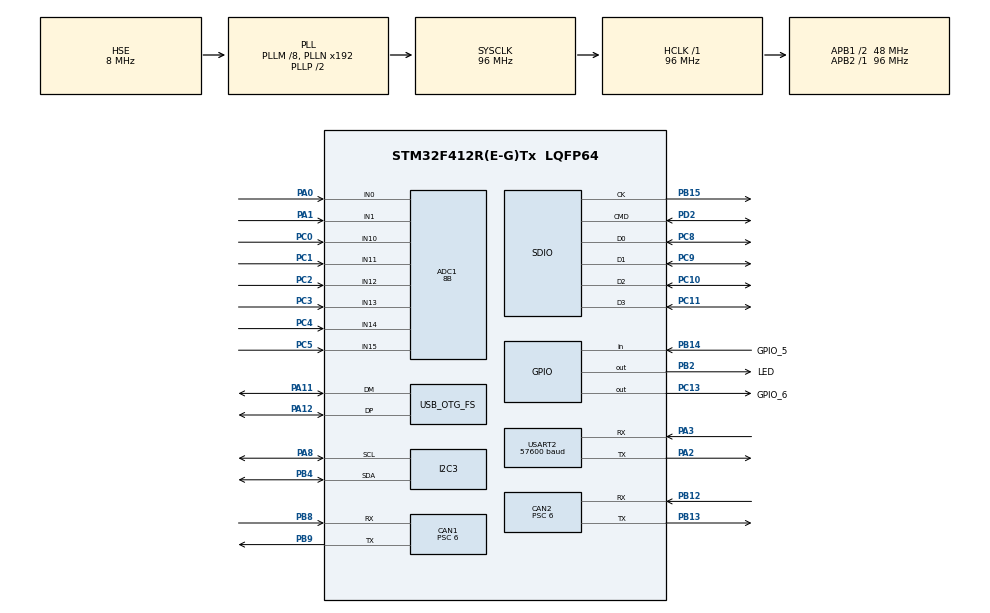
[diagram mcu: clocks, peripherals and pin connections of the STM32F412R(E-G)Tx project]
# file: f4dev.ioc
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ADC1.NbrOfConversionFlag=1
ADC1.Resolution=ADC_RESOLUTION_8B
ADC1.master=1
CAN1.ABOM=ENABLE
CAN1.BS1=CAN_BS1_13TQ
CAN1.BS2=CAN_BS2_2TQ
CAN1.CalculateBaudRate=500000
CAN1.CalculateTimeBit=2000
CAN1.CalculateTimeQuantum=125.0
CAN1.NART=ENABLE
CAN1.Prescaler=6
CAN1.RFLM=ENABLE
CAN1.SJW=CAN_SJW_4TQ
CAN1.TXFP=ENABLE
CAN2.ABOM=ENABLE
CAN2.BS1=CAN_BS1_13TQ
CAN2.BS2=CAN_BS2_2TQ
CAN2.CalculateBaudRate=500000
CAN2.CalculateTimeBit=2000
CAN2.CalculateTimeQuantum=125.0
CAN2.NART=ENABLE
CAN2.Prescaler=6
CAN2.RFLM=ENABLE
CAN2.TXFP=ENABLE
Mcu.Family=STM32F4
Mcu.Name=STM32F412R(E-G)Tx
Mcu.Package=LQFP64
NVIC.CAN1_RX0_IRQn=true\:0\:0\:false\:false\:true\:true\:true\:true
NVIC.CAN1_RX1_IRQn=true\:0\:0\:false\:false\:true\:true\:true\:true
NVIC.CAN2_RX0_IRQn=true\:0\:0\:false\:false\:true\:true\:true\:true
NVIC.CAN2_RX1_IRQn=true\:0\:0\:false\:false\:true\:true\:true\:true
NVIC.OTG_FS_IRQn=true\:0\:0\:false\:false\:true\:false\:true\:true
NVIC.PriorityGroup=NVIC_PRIORITYGROUP_4
NVIC.TIM6_IRQn=true\:15\:0\:false\:false\:true\:false\:true\:true
NVIC.TimeBase=TIM6_IRQn
NVIC.TimeBaseIP=TIM6
PA0.Signal=ADCx_IN0
PA1.Signal=ADCx_IN1
PA11.Mode=Device_Only
PA11.Signal=USB_OTG_FS_DM
PA12.Mode=Device_Only
PA12.Signal=USB_OTG_FS_DP
PA13.Mode=Trace_Asynchronous_SW
PA13.Signal=SYS_JTMS-SWDIO
PA14.Mode=Trace_Asynchronous_SW
PA14.Signal=SYS_JTCK-SWCLK
PA2.Mode=Asynchronous
PA2.Signal=USART2_TX
PA3.Mode=Asynchronous
PA3.Signal=USART2_RX
PA5.Signal=SPI1_SCK
PA6.Signal=SPI1_MISO
PA7.Signal=SPI1_MOSI
PA8.Mode=I2C
PA8.Signal=I2C3_SCL
PB0.Signal=S_TIM3_CH3
PB1.Signal=S_TIM3_CH4
PB12.Mode=CAN_Activate
PB12.Signal=CAN2_RX
PB13.Mode=CAN_Activate
PB13.Signal=CAN2_TX
PB14.GPIO_Label=GPIO_5
PB14.Signal=GPIO_Input
PB15.Mode=SD_4_bits_Wide_bus
PB15.Signal=SDIO_CK
PB2.GPIO_Label=LED
PB2.Signal=GPIO_Output
PB3.Mode=Trace_Asynchronous_SW
PB3.Signal=SYS_JTDO-SWO
PB4.Mode=I2C
PB4.Signal=I2C3_SDA
PB8.Mode=CAN_Activate
PB8.Signal=CAN1_RX
PB9.Mode=CAN_Activate
PB9.Signal=CAN1_TX
PC0.Signal=ADCx_IN10
PC1.Signal=ADCx_IN11
PC10.Mode=SD_4_bits_Wide_bus
PC10.Signal=SDIO_D2
PC11.Mode=SD_4_bits_Wide_bus
PC11.Signal=SDIO_D3
PC13.GPIO_Label=GPIO_6
PC13.Signal=GPIO_Output
PC2.Signal=ADCx_IN12
PC3.Signal=ADCx_IN13
PC4.Signal=ADCx_IN14
PC5.Signal=ADCx_IN15
PC6.Signal=S_TIM3_CH1
PC7.Signal=S_TIM3_CH2
PC8.Mode=SD_4_bits_Wide_bus
PC8.Signal=SDIO_D0
PC9.Mode=SD_4_bits_Wide_bus
PC9.Signal=SDIO_D1
PD2.Mode=SD_4_bits_Wide_bus
PD2.Signal=SDIO_CMD
PH0\ -\ OSC_IN.Mode=HSE-External-Oscillator
PH0\ -\ OSC_IN.Signal=RCC_OSC_IN
PH1\ -\ OSC_OUT.Mode=HSE-External-Oscillator
PH1\ -\ OSC_OUT.Signal=RCC_OSC_OUT
ProjectManager.HeapSize=0x00
ProjectManager.StackSize=0x400
ProjectManager.TargetToolchain=CMake
RCC.AHBFreq_Value=96000000
RCC.APB1CLKDivider=RCC_HCLK_DIV2
RCC.APB1Freq_Value=48000000
RCC.APB1TimFreq_Value=96000000
RCC.APB2Freq_Value=96000000
RCC.APB2TimFreq_Value=96000000
RCC.CortexFreq_Value=96000000
RCC.HCLKFreq_Value=96000000
RCC.HSE_VALUE=8000000
RCC.PLLM=8
RCC.PLLQ=4
RCC.PLLSourceVirtual=RCC_PLLSOURCE_HSE
RCC.SYSCLKFreq_VALUE=96000000
RCC.SYSCLKSource=RCC_SYSCLKSOURCE_PLLCLK
RCC.USBFreq_Value=48000000
RCC.VCOOutputFreq_Value=192000000
SH.ADCx_IN0.0=ADC1_IN0,IN0
SH.ADCx_IN1.0=ADC1_IN1,IN1
SH.ADCx_IN10.0=ADC1_IN10,IN10
SH.ADCx_IN11.0=ADC1_IN11,IN11
SH.ADCx_IN12.0=ADC1_IN12,IN12
SH.ADCx_IN13.0=ADC1_IN13,IN13
SH.ADCx_IN14.0=ADC1_IN14,IN14
SH.ADCx_IN15.0=ADC1_IN15,IN15
SH.S_TIM3_CH1.0=TIM3_CH1
SH.S_TIM3_CH2.0=TIM3_CH2
SH.S_TIM3_CH3.0=TIM3_CH3
SH.S_TIM3_CH4.0=TIM3_CH4
USART2.BaudRate=57600
USART2.VirtualMode=VM_ASYNC
USB_DEVICE.CLASS_NAME_FS=CDC
USB_DEVICE.MANUFACTURER_STRING=ubc_formula_electric
USB_DEVICE.PRODUCT_STRING_CDC_FS=f4dev
USB_DEVICE.VirtualMode=Cdc
USB_DEVICE.VirtualModeFS=Cdc_FS
USB_OTG_FS.VirtualMode=Device_Only
VP_SYS_VS_tim6.Mode=TIM6
VP_USB_DEVICE_VS_USB_DEVICE_CDC_FS.Mode=CDC_FS
board=custom

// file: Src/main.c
/* USER CODE BEGIN Header */
/**
 ******************************************************************************
 * @file           : main.c
 * @brief          : Main program body
 ******************************************************************************
 * @attention
 *
 * <h2><center>&copy; Copyright (c) 2023 STMicroelectronics.
 * All rights reserved.</center></h2>
 *
 * This software component is licensed by ST under BSD 3-Clause license,
 * the "License"; You may not use this file except in compliance with the
 * License. You may obtain a copy of the License at:
 *                        opensource.org/licenses/BSD-3-Clause
 *
 ******************************************************************************
 */
/* USER CODE END Header */
#include "main.h"
#include "usb_device.h"

/* USER CODE BEGIN Includes */
#include <assert.h>
#include "tasks.h"
/* USER CODE END Includes */

ADC_HandleTypeDef hadc1;

CAN_HandleTypeDef hcan1;
CAN_HandleTypeDef hcan2;

I2C_HandleTypeDef hi2c3;

SD_HandleTypeDef hsd;

UART_HandleTypeDef huart2;

void        SystemClock_Config(void);
static void MX_GPIO_Init(void);
static void MX_SDIO_SD_Init(void);
static void MX_CAN1_Init(void);
static void MX_ADC1_Init(void);
static void MX_CAN2_Init(void);
static void MX_USART2_UART_Init(void);
static void MX_I2C3_Init(void);

int main(void)
{

    /* MCU Configuration--------------------------------------------------------*/

    /* Reset of all peripherals, Initializes the Flash interface and the Systick. */
    HAL_Init();

    /* Configure the system clock */
    SystemClock_Config();

    /* Initialize all configured peripherals */
    MX_GPIO_Init();
    MX_SDIO_SD_Init();
    MX_CAN1_Init();
    MX_ADC1_Init();
    MX_CAN2_Init();
    MX_USART2_UART_Init();
    MX_USB_DEVICE_Init();
    MX_I2C3_Init();

    /* Infinite loop */
    while (1)
    {

    }
}

void SystemClock_Config(void)
{
    RCC_OscInitTypeDef RCC_OscInitStruct = { 0 };
    RCC_ClkInitTypeDef RCC_ClkInitStruct = { 0 };

    /** Configure the main internal regulator output voltage
     */
    __HAL_RCC_PWR_CLK_ENABLE();
    __HAL_PWR_VOLTAGESCALING_CONFIG(PWR_REGULATOR_VOLTAGE_SCALE1);

    /** Initializes the RCC Oscillators according to the specified parameters
     * in the RCC_OscInitTypeDef structure.
     */
    RCC_OscInitStruct.OscillatorType = RCC_OSCILLATORTYPE_HSE;
    RCC_OscInitStruct.HSEState       = RCC_HSE_ON;
    RCC_OscInitStruct.PLL.PLLState   = RCC_PLL_ON;
    RCC_OscInitStruct.PLL.PLLSource  = RCC_PLLSOURCE_HSE;
    RCC_OscInitStruct.PLL.PLLM       = 8;
    RCC_OscInitStruct.PLL.PLLN       = 192;
    RCC_OscInitStruct.PLL.PLLP       = RCC_PLLP_DIV2;
    RCC_OscInitStruct.PLL.PLLQ       = 4;
    RCC_OscInitStruct.PLL.PLLR       = 2;
    if (HAL_RCC_OscConfig(&RCC_OscInitStruct) != HAL_OK)
    {
        Error_Handler();
    }

    /** Initializes the CPU, AHB and APB buses clocks
     */
    RCC_ClkInitStruct.ClockType = RCC_CLOCKTYPE_HCLK | RCC_CLOCKTYPE_SYSCLK | RCC_CLOCKTYPE_PCLK1 | RCC_CLOCKTYPE_PCLK2;
    RCC_ClkInitStruct.SYSCLKSource   = RCC_SYSCLKSOURCE_PLLCLK;
    RCC_ClkInitStruct.AHBCLKDivider  = RCC_SYSCLK_DIV1;
    RCC_ClkInitStruct.APB1CLKDivider = RCC_HCLK_DIV2;
    RCC_ClkInitStruct.APB2CLKDivider = RCC_HCLK_DIV1;

    if (HAL_RCC_ClockConfig(&RCC_ClkInitStruct, FLASH_LATENCY_3) != HAL_OK)
    {
        Error_Handler();
    }
}

static void MX_ADC1_Init(void)
{

    /** Configure the global features of the ADC (Clock, Resolution, Data Alignment and number of conversion)
     */
    hadc1.Instance                   = ADC1;
    hadc1.Init.ClockPrescaler        = ADC_CLOCK_SYNC_PCLK_DIV4;
    hadc1.Init.Resolution            = ADC_RESOLUTION_8B;
    hadc1.Init.ScanConvMode          = DISABLE;
    hadc1.Init.ContinuousConvMode    = DISABLE;
    hadc1.Init.DiscontinuousConvMode = DISABLE;
    hadc1.Init.ExternalTrigConvEdge  = ADC_EXTERNALTRIGCONVEDGE_NONE;
    hadc1.Init.ExternalTrigConv      = ADC_SOFTWARE_START;
    hadc1.Init.DataAlign             = ADC_DATAALIGN_RIGHT;
    hadc1.Init.NbrOfConversion       = 1;
    hadc1.Init.DMAContinuousRequests = DISABLE;
    hadc1.Init.EOCSelection          = ADC_EOC_SINGLE_CONV;
    if (HAL_ADC_Init(&hadc1) != HAL_OK)
    {
        Error_Handler();
    }
}

static void MX_CAN1_Init(void)
{

    hcan1.Instance                  = CAN1;
    hcan1.Init.Prescaler            = 6;
    hcan1.Init.Mode                 = CAN_MODE_NORMAL;
    hcan1.Init.SyncJumpWidth        = CAN_SJW_4TQ;
    hcan1.Init.TimeSeg1             = CAN_BS1_13TQ;
    hcan1.Init.TimeSeg2             = CAN_BS2_2TQ;
    hcan1.Init.TimeTriggeredMode    = DISABLE;
    hcan1.Init.AutoBusOff           = ENABLE;
    hcan1.Init.AutoWakeUp           = DISABLE;
    hcan1.Init.AutoRetransmission   = ENABLE;
    hcan1.Init.ReceiveFifoLocked    = ENABLE;
    hcan1.Init.TransmitFifoPriority = ENABLE;
    if (HAL_CAN_Init(&hcan1) != HAL_OK)
    {
        Error_Handler();
    }
}

static void MX_CAN2_Init(void)
{

    hcan2.Instance                  = CAN2;
    hcan2.Init.Prescaler            = 6;
    hcan2.Init.Mode                 = CAN_MODE_NORMAL;
    hcan2.Init.SyncJumpWidth        = CAN_SJW_1TQ;
    hcan2.Init.TimeSeg1             = CAN_BS1_13TQ;
    hcan2.Init.TimeSeg2             = CAN_BS2_2TQ;
    hcan2.Init.TimeTriggeredMode    = DISABLE;
    hcan2.Init.AutoBusOff           = ENABLE;
    hcan2.Init.AutoWakeUp           = DISABLE;
    hcan2.Init.AutoRetransmission   = ENABLE;
    hcan2.Init.ReceiveFifoLocked    = ENABLE;
    hcan2.Init.TransmitFifoPriority = ENABLE;
    if (HAL_CAN_Init(&hcan2) != HAL_OK)
    {
        Error_Handler();
    }
}

static void MX_I2C3_Init(void)
{

    hi2c3.Instance             = I2C3;
    hi2c3.Init.ClockSpeed      = 100000;
    hi2c3.Init.DutyCycle       = I2C_DUTYCYCLE_2;
    hi2c3.Init.OwnAddress1     = 0;
    hi2c3.Init.AddressingMode  = I2C_ADDRESSINGMODE_7BIT;
    hi2c3.Init.DualAddressMode = I2C_DUALADDRESS_DISABLE;
    hi2c3.Init.OwnAddress2     = 0;
    hi2c3.Init.GeneralCallMode = I2C_GENERALCALL_DISABLE;
    hi2c3.Init.NoStretchMode   = I2C_NOSTRETCH_DISABLE;
    if (HAL_I2C_Init(&hi2c3) != HAL_OK)
    {
        Error_Handler();
    }
}

static void MX_SDIO_SD_Init(void)
{

    hsd.Instance                 = SDIO;
    hsd.Init.ClockEdge           = SDIO_CLOCK_EDGE_RISING;
    hsd.Init.ClockBypass         = SDIO_CLOCK_BYPASS_DISABLE;
    hsd.Init.ClockPowerSave      = SDIO_CLOCK_POWER_SAVE_DISABLE;
    hsd.Init.BusWide             = SDIO_BUS_WIDE_4B;
    hsd.Init.HardwareFlowControl = SDIO_HARDWARE_FLOW_CONTROL_DISABLE;
    hsd.Init.ClockDiv            = 0;
    if (HAL_SD_Init(&hsd) != HAL_OK)
    {
        Error_Handler();
    }
    if (HAL_SD_ConfigWideBusOperation(&hsd, SDIO_BUS_WIDE_4B) != HAL_OK)
    {
        Error_Handler();
    }
}

static void MX_USART2_UART_Init(void)
{

    huart2.Instance          = USART2;
    huart2.Init.BaudRate     = 57600;
    huart2.Init.WordLength   = UART_WORDLENGTH_8B;
    huart2.Init.StopBits     = UART_STOPBITS_1;
    huart2.Init.Parity       = UART_PARITY_NONE;
    huart2.Init.Mode         = UART_MODE_TX_RX;
    huart2.Init.HwFlowCtl    = UART_HWCONTROL_NONE;
    huart2.Init.OverSampling = UART_OVERSAMPLING_16;
    if (HAL_UART_Init(&huart2) != HAL_OK)
    {
        Error_Handler();
    }
}

static void MX_GPIO_Init(void)
{
    GPIO_InitTypeDef GPIO_InitStruct = { 0 };

    /* GPIO Ports Clock Enable */
    __HAL_RCC_GPIOC_CLK_ENABLE();
    __HAL_RCC_GPIOH_CLK_ENABLE();
    __HAL_RCC_GPIOA_CLK_ENABLE();
    __HAL_RCC_GPIOB_CLK_ENABLE();
    __HAL_RCC_GPIOD_CLK_ENABLE();

    /*Configure GPIO pin Output Level */
    HAL_GPIO_WritePin(GPIO_6_GPIO_Port, GPIO_6_Pin, GPIO_PIN_RESET);

    /*Configure GPIO pin Output Level */
    HAL_GPIO_WritePin(LED_GPIO_Port, LED_Pin, GPIO_PIN_RESET);

    /*Configure GPIO pin : GPIO_6_Pin */
    GPIO_InitStruct.Pin   = GPIO_6_Pin;
    GPIO_InitStruct.Mode  = GPIO_MODE_OUTPUT_PP;
    GPIO_InitStruct.Pull  = GPIO_NOPULL;
    GPIO_InitStruct.Speed = GPIO_SPEED_FREQ_LOW;
    HAL_GPIO_Init(GPIO_6_GPIO_Port, &GPIO_InitStruct);

    /*Configure GPIO pins : PA5 PA6 PA7 */
    GPIO_InitStruct.Pin       = GPIO_PIN_5 | GPIO_PIN_6 | GPIO_PIN_7;
    GPIO_InitStruct.Mode      = GPIO_MODE_AF_PP;
    GPIO_InitStruct.Pull      = GPIO_NOPULL;
    GPIO_InitStruct.Speed     = GPIO_SPEED_FREQ_VERY_HIGH;
    GPIO_InitStruct.Alternate = GPIO_AF5_SPI1;
    HAL_GPIO_Init(GPIOA, &GPIO_InitStruct);

    /*Configure GPIO pins : PB0 PB1 */
    GPIO_InitStruct.Pin       = GPIO_PIN_0 | GPIO_PIN_1;
    GPIO_InitStruct.Mode      = GPIO_MODE_AF_PP;
    GPIO_InitStruct.Pull      = GPIO_NOPULL;
    GPIO_InitStruct.Speed     = GPIO_SPEED_FREQ_LOW;
    GPIO_InitStruct.Alternate = GPIO_AF2_TIM3;
    HAL_GPIO_Init(GPIOB, &GPIO_InitStruct);

    /*Configure GPIO pin : LED_Pin */
    GPIO_InitStruct.Pin   = LED_Pin;
    GPIO_InitStruct.Mode  = GPIO_MODE_OUTPUT_PP;
    GPIO_InitStruct.Pull  = GPIO_NOPULL;
    GPIO_InitStruct.Speed = GPIO_SPEED_FREQ_LOW;
    HAL_GPIO_Init(LED_GPIO_Port, &GPIO_InitStruct);

    /*Configure GPIO pin : GPIO_5_Pin */
    GPIO_InitStruct.Pin  = GPIO_5_Pin;
    GPIO_InitStruct.Mode = GPIO_MODE_INPUT;
    GPIO_InitStruct.Pull = GPIO_NOPULL;
    HAL_GPIO_Init(GPIO_5_GPIO_Port, &GPIO_InitStruct);

    /*Configure GPIO pins : PC6 PC7 */
    GPIO_InitStruct.Pin       = GPIO_PIN_6 | GPIO_PIN_7;
    GPIO_InitStruct.Mode      = GPIO_MODE_AF_PP;
    GPIO_InitStruct.Pull      = GPIO_NOPULL;
    GPIO_InitStruct.Speed     = GPIO_SPEED_FREQ_LOW;
    GPIO_InitStruct.Alternate = GPIO_AF2_TIM3;
    HAL_GPIO_Init(GPIOC, &GPIO_InitStruct);

}

void HAL_TIM_PeriodElapsedCallback(TIM_HandleTypeDef *htim)
{
    if (htim->Instance == TIM6)
    {
        HAL_IncTick();
    }
}

void Error_Handler(void)
{
}
